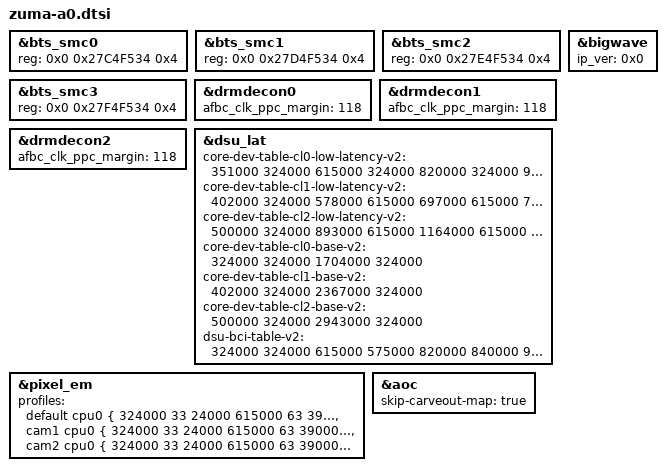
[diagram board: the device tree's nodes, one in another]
// SPDX-License-Identifier: GPL-2.0-only
/*
 * Copyright 2021 Google LLC.
 *
 */

#include "zuma.dtsi"

&bts_smc0 {
	reg = <0x0 0x27C4F534 0x4>;
};

&bts_smc1 {
	reg = <0x0 0x27D4F534 0x4>;
};

&bts_smc2 {
	reg = <0x0 0x27E4F534 0x4>;
};

&bts_smc3 {
	reg = <0x0 0x27F4F534 0x4>;
};

&drmdecon0 {
	afbc_clk_ppc_margin = <118>; /* additional 18% margin for afbc layer clock */
};

&drmdecon1 {
	afbc_clk_ppc_margin = <118>; /* additional 18% margin for afbc layer clock */
};

&drmdecon2 {
	afbc_clk_ppc_margin = <118>; /* additional 18% margin for afbc layer clock */
};

&dsu_lat {
	core-dev-table-cl0-low-latency-v2 =
		/* CL0         DSU */
		< 351000        324000
		615000        324000
		820000        324000
		975000        615000
		1098000       615000
		1197000       820000
		1328000       820000
		1475000       820000
		1548000       820000
		1704000       820000
		1844000       820000
		1950000       820000
		2024000       820000
		2098000       820000
		2147000       820000
		2253000       820000 >;

	core-dev-table-cl1-low-latency-v2 =
		/* CL1         DSU */
		< 402000        324000
		578000        615000
		697000        615000
		721000        615000
		910000        615000
		1082000       615000
		1221000       615000
		1328000       615000
		1418000       615000
		1549000       820000
		1622000       820000
		1836000       820000
		1999000       820000
		2130000       820000
		2245000       820000
		2352000       820000
		2450000       820000
		2550000       820000
		2600000       820000 >;

	core-dev-table-cl2-low-latency-v2 =
		/* CL2         DSU */
		< 500000        324000
		893000        615000
		1164000       615000
		1328000       820000
		1557000       975000
		1745000       975000
		1852000       975000
		1901000       975000
		2049000       975000
		2147000       975000
		2294000       975000
		2409000       975000
		2556000       975000
		2687000       975000
		2802000       975000
		2914000       975000
		3015000       975000
		3178000       975000
		3310000       975000 >;

	core-dev-table-cl0-base-v2 =
		<  324000        324000
		  1704000        324000 >;

	core-dev-table-cl1-base-v2 =
		<  402000       324000
		  2367000       324000 >;

	core-dev-table-cl2-base-v2 =
		<  500000       324000
		  2943000       324000 >;

	dsu-bci-table-v2 =
		/* DSU         BCI */
		< 324000        324000
		615000        575000
		820000        840000
		975000        840000 >;
};

&pixel_em {
		profiles =
			"default
				cpu0 {
				324000 33 24000
				615000 63 39000
				820000 84 56000
				975000 100 73000
				1098000 113 86000
				1197000 123 98000
				1328000 136 116000
				1475000 152 141000
				1548000 159 158000
				1704000 175 198000
				1844000 189 242000
				1950000 201 289000
				2024000 208 328000
				2098000 216 370000
				2147000 220 396000
				}
				cpu4 {
				402000 118 56000
				578000 170 84000
				697000 205 105000
				721000 212 107000
				910000 268 148000
				1082000 318 201000
				1221000 359 251000
				1328000 405 304000
				1418000 439 356000
				1549000 456 405000
				1622000 478 439000
				1836000 540 596000
				1999000 588 743000
				2130000 629 930000
				2245000 661 1122000
				2352000 692 1314000
				2450000 721 1515000
				}
				cpu8 {
				500000 171 121000
				893000 288 225000
				1164000 399 342000
				1328000 443 415000
				1557000 507 544000
				1745000 571 682000
				1852000 609 765000
				1901000 618 799000
				2049000 680 983000
				2147000 714 1134000
				2294000 748 1322000
				2409000 794 1481000
				2556000 850 1883000
				2687000 923 2377000
				2802000 972 2882000
				2914000 999 3465000
				3015000 1024 3954000
				}
			",
			"cam1
				cpu0 {
				324000 33 24000
				615000 63 39000
				820000 84 56000
				975000 100 73000
				1098000 113 86000
				1197000 123 98000
				1328000 136 116000
				1475000 152 141000
				1548000 159 158000
				1704000 175 198000
				1844000 189 242000
				1950000 201 289000
				2024000 208 328000
				2098000 216 370000
				2147000 220 396000
				}
				cpu4 {
				402000 118 56000
				578000 170 84000
				697000 205 105000
				721000 212 107000
				910000 268 148000
				1082000 318 201000
				1221000 359 251000
				1328000 405 304000
				1418000 439 356000
				1549000 456 405000
				1622000 478 439000
				1836000 540 596000
				1999000 588 743000
				2130000 629 930000
				2245000 661 1122000
				2352000 692 1314000
				2450000 721 1515000
				}
				cpu8 {
				500000 171 121000
				893000 288 225000
				1164000 399 342000
				1328000 443 415000
				1557000 507 544000
				1745000 571 682000
				1852000 609 765000
				1901000 618 799000
				2049000 680 983000
				2147000 714 1134000
				2294000 748 1322000
				2409000 794 1481000
				2556000 850 1883000
				2687000 923 2377000
				2802000 972 2882000
				2914000 999 3465000
				3015000 1024 3954000
				}
			",
			"cam2
				cpu0 {
				324000 33 24000
				615000 63 39000
				820000 84 56000
				975000 100 73000
				1098000 113 86000
				1197000 123 98000
				1328000 136 116000
				1475000 152 141000
				1548000 159 158000
				1704000 175 198000
				1844000 189 242000
				1950000 201 289000
				2024000 208 328000
				2098000 216 370000
				2147000 220 396000
				}
				cpu4 {
				402000 118 56000
				578000 170 84000
				697000 205 105000
				721000 212 107000
				910000 268 148000
				1082000 318 201000
				1221000 359 251000
				1328000 405 304000
				1418000 439 356000
				1549000 456 405000
				1622000 478 439000
				1836000 540 596000
				1999000 588 743000
				2130000 629 930000
				2245000 661 1122000
				2352000 692 1314000
				2450000 721 1515000
				}
				cpu8 {
				500000 171 121000
				893000 288 225000
				1164000 399 342000
				1328000 443 415000
				1557000 507 544000
				1745000 571 682000
				1852000 609 765000
				1901000 618 799000
				2049000 680 983000
				2147000 714 1134000
				2294000 748 1322000
				2409000 794 1481000
				2556000 850 1883000
				2687000 923 2377000
				2802000 972 2882000
				2914000 999 3465000
				3015000 1024 3954000
				}
			";
};

&aoc {
    skip-carveout-map = "true";
};

&bigwave {
	ip_ver = <0x0>;
};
